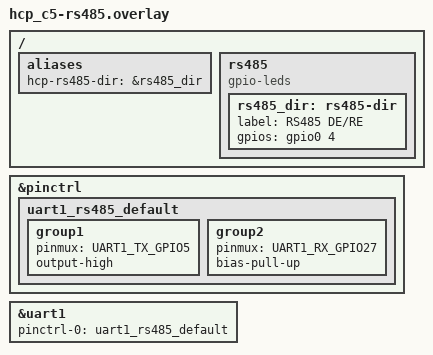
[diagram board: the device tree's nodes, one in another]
/*
 * ESP32-C5 RS485 variant overlay (mutually exclusive with the default TTL).
 * Applied via: build.sh hcp_c5/... --rs485
 * Re-pins UART1 to the c5-485 physical pads (TX=GPIO5, RX=GPIO27) and adds the
 * DE/RE direction line for the external TTL->RS485 transceiver (DE=GPIO4),
 * exported as alias `hcp-rs485-dir` so the serial backend toggles it.
 */

#include <zephyr/dt-bindings/gpio/gpio.h>
#include <zephyr/dt-bindings/pinctrl/esp32c5-pinctrl.h>
#include <zephyr/dt-bindings/pinctrl/esp32c5-gpio-sigmap.h>

/ {
	aliases {
		hcp-rs485-dir = &rs485_dir;
	};

	rs485 {
		compatible = "gpio-leds";
		rs485_dir: rs485-dir {
			label = "RS485 DE/RE";
			gpios = <&gpio0 4 GPIO_ACTIVE_HIGH>;
		};
	};
};

&pinctrl {
	uart1_rs485_default: uart1_rs485_default {
		group1 {
			pinmux = <UART1_TX_GPIO5>;
			output-high;
		};
		group2 {
			pinmux = <UART1_RX_GPIO27>;
			bias-pull-up;
		};
	};
};

&uart1 {
	pinctrl-0 = <&uart1_rs485_default>;
};
